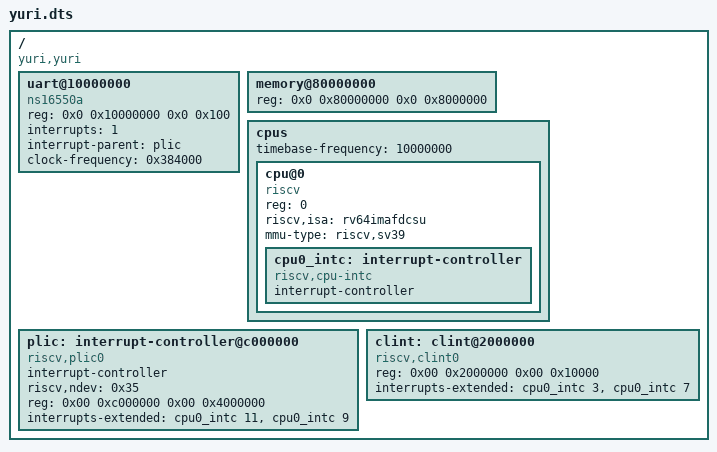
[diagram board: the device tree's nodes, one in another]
/dts-v1/;

/ {
    #address-cells = <2>;
    #size-cells = <2>;
    compatible = "yuri,yuri";

    uart@10000000 {
        compatible = "ns16550a";
        reg = <0x0 0x10000000 0x0 0x100>;
        interrupts = <1>;
        interrupt-parent = <&plic>;
        clock-frequency = <0x384000>;
    };

    memory@80000000 {
    	device_type = "memory";
    	reg = <0x0 0x80000000 0x0 0x8000000>;
    };

    cpus {
        #address-cells = <1>;
        #size-cells = <0>;
        timebase-frequency = <10000000>;
        cpu@0 {
            device_type = "cpu";
            compatible = "riscv";
            reg = <0>;
            status = "okay";
            riscv,isa = "rv64imafdcsu";
            mmu-type = "riscv,sv39";
            cpu0_intc: interrupt-controller {
                #interrupt-cells = <0x01>;
                interrupt-controller;
                compatible = "riscv,cpu-intc";
            };
        };
    };

    plic: interrupt-controller@c000000 {
        #interrupt-cells = <1>;
        #address-cells = <0>;
        compatible = "riscv,plic0";
        interrupt-controller;
        riscv,ndev = <0x35>;
        reg = <0x00 0xc000000 0x00 0x4000000>;
        interrupts-extended = <&cpu0_intc 11 &cpu0_intc 9>;
    };

    clint: clint@2000000 {
        compatible = "riscv,clint0";
        reg = <0x00 0x2000000 0x00 0x10000>;
        interrupts-extended = <&cpu0_intc 3 &cpu0_intc 7>;
    };
};
